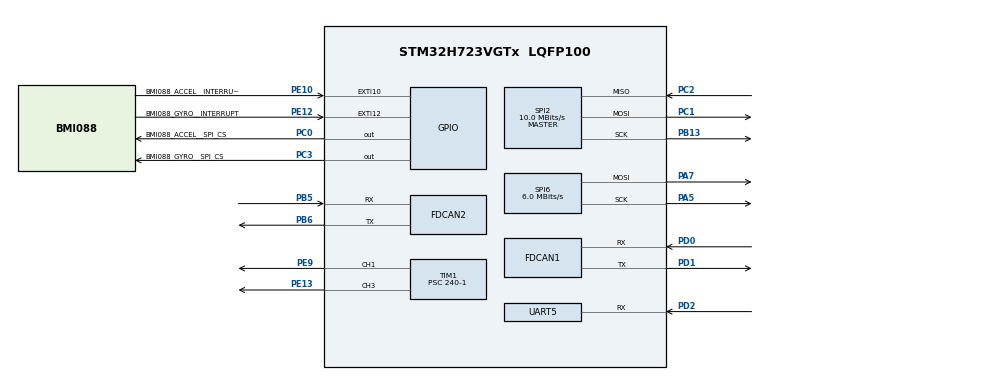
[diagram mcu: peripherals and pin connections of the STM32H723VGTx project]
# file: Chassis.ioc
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CORTEX_M7.CPU_DCache=Disabled
CORTEX_M7.CPU_ICache=Disabled
Dma.Request0=UART5_RX
Dma.UART5_RX.0.Direction=DMA_PERIPH_TO_MEMORY
Dma.UART5_RX.0.EventEnable=DISABLE
Dma.UART5_RX.0.FIFOMode=DMA_FIFOMODE_DISABLE
Dma.UART5_RX.0.Instance=DMA1_Stream1
Dma.UART5_RX.0.MemDataAlignment=DMA_MDATAALIGN_BYTE
Dma.UART5_RX.0.MemInc=DMA_MINC_ENABLE
Dma.UART5_RX.0.Mode=DMA_NORMAL
Dma.UART5_RX.0.PeriphDataAlignment=DMA_PDATAALIGN_BYTE
Dma.UART5_RX.0.PeriphInc=DMA_PINC_DISABLE
Dma.UART5_RX.0.Polarity=HAL_DMAMUX_REQ_GEN_RISING
Dma.UART5_RX.0.Priority=DMA_PRIORITY_VERY_HIGH
Dma.UART5_RX.0.RequestNumber=1
Dma.UART5_RX.0.SignalID=NONE
Dma.UART5_RX.0.SyncEnable=DISABLE
Dma.UART5_RX.0.SyncPolarity=HAL_DMAMUX_SYNC_NO_EVENT
Dma.UART5_RX.0.SyncRequestNumber=1
Dma.UART5_RX.0.SyncSignalID=NONE
FDCAN1.AutoRetransmission=ENABLE
FDCAN1.CalculateBaudRateNominal=1000000
FDCAN1.CalculateTimeBitNominal=1000
FDCAN1.CalculateTimeQuantumNominal=25.0
FDCAN1.DataPrescaler=3
FDCAN1.DataSyncJumpWidth=10
FDCAN1.DataTimeSeg1=29
FDCAN1.DataTimeSeg2=10
FDCAN1.ExtFiltersNbr=0
FDCAN1.FrameFormat=FDCAN_FRAME_CLASSIC
FDCAN1.Mode=FDCAN_MODE_NORMAL
FDCAN1.NominalPrescaler=3
FDCAN1.NominalSyncJumpWidth=10
FDCAN1.NominalTimeSeg1=29
FDCAN1.NominalTimeSeg2=10
FDCAN1.ProtocolException=DISABLE
FDCAN1.RxBuffersNbr=0
FDCAN1.RxFifo0ElmtsNbr=4
FDCAN1.RxFifo1ElmtsNbr=0
FDCAN1.StdFiltersNbr=1
FDCAN1.TransmitPause=ENABLE
FDCAN1.TxBuffersNbr=0
FDCAN1.TxEventsNbr=0
FDCAN1.TxFifoQueueElmtsNbr=4
FDCAN2.AutoRetransmission=ENABLE
FDCAN2.CalculateBaudRateNominal=1000000
FDCAN2.CalculateTimeBitNominal=1000
FDCAN2.CalculateTimeQuantumNominal=25.0
FDCAN2.DataPrescaler=3
FDCAN2.DataSyncJumpWidth=10
FDCAN2.DataTimeSeg1=29
FDCAN2.DataTimeSeg2=10
FDCAN2.ExtFiltersNbr=0
FDCAN2.FrameFormat=FDCAN_FRAME_CLASSIC
FDCAN2.MessageRAMOffset=0x406
FDCAN2.Mode=FDCAN_MODE_NORMAL
FDCAN2.NominalPrescaler=3
FDCAN2.NominalSyncJumpWidth=10
FDCAN2.NominalTimeSeg1=29
FDCAN2.NominalTimeSeg2=10
FDCAN2.ProtocolException=DISABLE
FDCAN2.RxBuffersNbr=0
FDCAN2.RxFifo0ElmtsNbr=4
FDCAN2.RxFifo1ElmtsNbr=0
FDCAN2.StdFiltersNbr=1
FDCAN2.TransmitPause=ENABLE
FDCAN2.TxBuffersNbr=0
FDCAN2.TxEventsNbr=0
FDCAN2.TxFifoQueueElmtsNbr=4
FREERTOS.Tasks01=defaultTask,24,128,StartDefaultTask,Default,NULL,Dynamic,NULL,NULL;ChassisTask,40,512,Chassis_Task,As external,NULL,Dynamic,NULL,NULL;CommunicateTask,24,512,Communicate_Task,As external,NULL,Dynamic,NULL,NULL;ShootTask,32,512,Shoot_Task,As external,NULL,Dynamic,NULL,NULL
Mcu.Family=STM32H7
Mcu.Name=STM32H723VGTx
Mcu.Package=LQFP100
NVIC.DMA1_Stream1_IRQn=true\:5\:0\:false\:false\:true\:false\:false\:true\:true
NVIC.EXTI15_10_IRQn=true\:5\:0\:false\:false\:true\:true\:true\:true\:true
NVIC.FDCAN1_IT0_IRQn=true\:5\:0\:true\:false\:true\:true\:true\:true\:true
NVIC.FDCAN1_IT1_IRQn=true\:5\:0\:true\:false\:true\:true\:true\:true\:true
NVIC.FDCAN2_IT0_IRQn=true\:5\:0\:false\:false\:true\:true\:true\:true\:true
NVIC.FDCAN2_IT1_IRQn=true\:5\:0\:false\:false\:true\:true\:true\:true\:true
NVIC.PriorityGroup=NVIC_PRIORITYGROUP_4
NVIC.TIM23_IRQn=true\:15\:0\:false\:false\:true\:false\:false\:true\:true
NVIC.TimeBase=TIM23_IRQn
NVIC.TimeBaseIP=TIM23
NVIC.UART5_IRQn=true\:5\:0\:false\:false\:true\:true\:true\:true\:true
PA13(JTMS/SWDIO).Mode=Serial_Wire
PA13(JTMS/SWDIO).Signal=DEBUG_JTMS-SWDIO
PA14(JTCK/SWCLK).Mode=Serial_Wire
PA14(JTCK/SWCLK).Signal=DEBUG_JTCK-SWCLK
PA5.Mode=TX_Only_Simplex_Unidirect_Master
PA5.Signal=SPI6_SCK
PA7.Mode=TX_Only_Simplex_Unidirect_Master
PA7.Signal=SPI6_MOSI
PB13.Mode=Full_Duplex_Master
PB13.Signal=SPI2_SCK
PB5.Mode=FDCAN_Activate
PB5.Signal=FDCAN2_RX
PB6.Mode=FDCAN_Activate
PB6.Signal=FDCAN2_TX
PD0.Mode=FDCAN_Activate
PD0.Signal=FDCAN1_RX
PD1.Mode=FDCAN_Activate
PD1.Signal=FDCAN1_TX
PD2.Mode=Asynchronous
PD2.Signal=UART5_RX
PC0.GPIO_Label=BMI088_ACCEL__SPI_CS
PC0.Signal=GPIO_Output
PC1.Mode=Full_Duplex_Master
PC1.Signal=SPI2_MOSI
PC2.Mode=Full_Duplex_Master
PC2.Signal=SPI2_MISO
PC3.GPIO_Label=BMI088_GYRO__SPI_CS
PC3.Signal=GPIO_Output
PE10.GPIO_Label=BMI088_ACCEL__INTERRUPT
PE10.GPIO_PuPd=GPIO_PULLDOWN
PE10.Signal=GPXTI10
PE12.GPIO_Label=BMI088_GYRO__INTERRUPT
PE12.GPIO_PuPd=GPIO_PULLDOWN
PE12.Signal=GPXTI12
PE13.GPIO_PuPd=GPIO_PULLDOWN
PE13.Signal=S_TIM1_CH3
PE9.GPIO_PuPd=GPIO_PULLDOWN
PE9.Signal=S_TIM1_CH1
PH0-OSC_IN.Mode=HSE-External-Oscillator
PH0-OSC_IN.Signal=RCC_OSC_IN
PH1-OSC_OUT.Mode=HSE-External-Oscillator
PH1-OSC_OUT.Signal=RCC_OSC_OUT
ProjectManager.HeapSize=0x200
ProjectManager.StackSize=0x800
ProjectManager.TargetToolchain=MDK-ARM V5.32
RCC.ADCFreq_Value=48375000
RCC.APB1Freq_Value=120000000
RCC.APB2Freq_Value=120000000
RCC.APB3Freq_Value=120000000
RCC.APB4Freq_Value=120000000
RCC.CortexFreq_Value=480000000
RCC.D1PPRE=RCC_APB3_DIV2
RCC.D2PPRE1=RCC_APB1_DIV2
RCC.D2PPRE2=RCC_APB2_DIV2
RCC.D3PPRE=RCC_APB4_DIV2
RCC.DIVM1=2
RCC.DIVN1=40
RCC.DIVP1=1
RCC.DIVQ1=4
RCC.HCLKFreq_Value=240000000
RCC.HPRE=RCC_HCLK_DIV2
RCC.HSE_VALUE=24000000
RCC.PLLFRACN=0
RCC.PLLSourceVirtual=RCC_PLLSOURCE_HSE
RCC.SPI6CLockSelection=RCC_SPI6CLKSOURCE_HSE
RCC.SYSCLKFreq_VALUE=480000000
RCC.SYSCLKSource=RCC_SYSCLKSOURCE_PLLCLK
RCC.USBFreq_Value=120000000
SH.S_TIM1_CH1.0=TIM1_CH1,PWM Generation1 CH1
SH.S_TIM1_CH3.0=TIM1_CH3,PWM Generation3 CH3
SPI2.BaudRatePrescaler=SPI_BAUDRATEPRESCALER_8
SPI2.CLKPhase=SPI_PHASE_2EDGE
SPI2.CLKPolarity=SPI_POLARITY_HIGH
SPI2.CalculateBaudRate=10.0 MBits/s
SPI2.DataSize=SPI_DATASIZE_8BIT
SPI2.Direction=SPI_DIRECTION_2LINES
SPI2.Mode=SPI_MODE_MASTER
SPI2.VirtualType=VM_MASTER
SPI6.BaudRatePrescaler=SPI_BAUDRATEPRESCALER_4
SPI6.CLKPhase=SPI_PHASE_2EDGE
SPI6.CalculateBaudRate=6.0 MBits/s
SPI6.DataSize=SPI_DATASIZE_8BIT
SPI6.Direction=SPI_DIRECTION_2LINES_TXONLY
SPI6.Mode=SPI_MODE_MASTER
SPI6.VirtualType=VM_MASTER
TIM1.AutoReloadPreload=TIM_AUTORELOAD_PRELOAD_ENABLE
TIM1.Channel-PWM\ Generation1\ CH1=TIM_CHANNEL_1
TIM1.Channel-PWM\ Generation3\ CH3=TIM_CHANNEL_3
TIM1.Period=2000-1
TIM1.Prescaler=240-1
UART5.BaudRate=100000
UART5.Mode=MODE_RX
UART5.Parity=PARITY_EVEN
UART5.StopBits=UART_STOPBITS_2
UART5.WordLength=WORDLENGTH_9B
VP_FREERTOS_VS_CMSIS_V2.Mode=CMSIS_V2
VP_MEMORYMAP_VS_MEMORYMAP.Mode=CurAppReg
VP_SYS_VS_tim23.Mode=TIM23
VP_TIM1_VS_ClockSourceINT.Mode=Internal
board=custom

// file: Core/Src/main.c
/* USER CODE BEGIN Header */
/**
  ******************************************************************************
  * @file           : main.c
  * @brief          : Main program body
  ******************************************************************************
  * @attention
  *
  * Copyright (c) 2026 STMicroelectronics.
  * All rights reserved.
  *
  * This software is licensed under terms that can be found in the LICENSE file
  * in the root directory of this software component.
  * If no LICENSE file comes with this software, it is provided AS-IS.
  *
  ******************************************************************************
  */
/* USER CODE END Header */
#include "main.h"
#include "FreeRTOS.h"
#include "cmsis_os2.h"
#include "dma.h"
#include "fdcan.h"
#include "spi.h"
#include "tim.h"
#include "usart.h"
#include "gpio.h"

/* USER CODE BEGIN Includes */
#include "bsp_fdcan.h"
#include "bsp_pwm.h"
extern void i6x_remote_init(void);
/* USER CODE END Includes */

void SystemClock_Config(void);
void MX_FREERTOS_Init(void);

int main(void)
{

  /* MCU Configuration--------------------------------------------------------*/

  /* Reset of all peripherals, Initializes the Flash interface and the Systick. */
  HAL_Init();

  /* Configure the system clock */
  SystemClock_Config();

  /* Initialize all configured peripherals */
  MX_GPIO_Init();
  MX_DMA_Init();
  MX_FDCAN1_Init();
  MX_FDCAN2_Init();
  MX_SPI2_Init();
  MX_SPI6_Init();
  MX_UART5_Init();
  MX_TIM1_Init();
  /* USER CODE BEGIN 2 */
  can_bsp_init();
  i6x_remote_init();
  pwm_init();
  /* USER CODE END 2 */

  /* Init scheduler */
  osKernelInitialize();  /* Call init function for freertos objects (in cmsis_os2.c) */
  MX_FREERTOS_Init();

  /* Start scheduler */
  osKernelStart();

  /* We should never get here as control is now taken by the scheduler */

  /* Infinite loop */
  while (1)
  {

  }
}

void SystemClock_Config(void)
{
  RCC_OscInitTypeDef RCC_OscInitStruct = {0};
  RCC_ClkInitTypeDef RCC_ClkInitStruct = {0};

  /** Supply configuration update enable
  */
  HAL_PWREx_ConfigSupply(PWR_LDO_SUPPLY);

  /** Configure the main internal regulator output voltage
  */
  __HAL_PWR_VOLTAGESCALING_CONFIG(PWR_REGULATOR_VOLTAGE_SCALE0);

  while(!__HAL_PWR_GET_FLAG(PWR_FLAG_VOSRDY)) {}

  /** Initializes the RCC Oscillators according to the specified parameters
  * in the RCC_OscInitTypeDef structure.
  */
  RCC_OscInitStruct.OscillatorType = RCC_OSCILLATORTYPE_HSE;
  RCC_OscInitStruct.HSEState = RCC_HSE_ON;
  RCC_OscInitStruct.PLL.PLLState = RCC_PLL_ON;
  RCC_OscInitStruct.PLL.PLLSource = RCC_PLLSOURCE_HSE;
  RCC_OscInitStruct.PLL.PLLM = 2;
  RCC_OscInitStruct.PLL.PLLN = 40;
  RCC_OscInitStruct.PLL.PLLP = 1;
  RCC_OscInitStruct.PLL.PLLQ = 4;
  RCC_OscInitStruct.PLL.PLLR = 2;
  RCC_OscInitStruct.PLL.PLLRGE = RCC_PLL1VCIRANGE_3;
  RCC_OscInitStruct.PLL.PLLVCOSEL = RCC_PLL1VCOWIDE;
  RCC_OscInitStruct.PLL.PLLFRACN = 0;
  if (HAL_RCC_OscConfig(&RCC_OscInitStruct) != HAL_OK)
  {
    Error_Handler();
  }

  /** Initializes the CPU, AHB and APB buses clocks
  */
  RCC_ClkInitStruct.ClockType = RCC_CLOCKTYPE_HCLK|RCC_CLOCKTYPE_SYSCLK
                              |RCC_CLOCKTYPE_PCLK1|RCC_CLOCKTYPE_PCLK2
                              |RCC_CLOCKTYPE_D3PCLK1|RCC_CLOCKTYPE_D1PCLK1;
  RCC_ClkInitStruct.SYSCLKSource = RCC_SYSCLKSOURCE_PLLCLK;
  RCC_ClkInitStruct.SYSCLKDivider = RCC_SYSCLK_DIV1;
  RCC_ClkInitStruct.AHBCLKDivider = RCC_HCLK_DIV2;
  RCC_ClkInitStruct.APB3CLKDivider = RCC_APB3_DIV2;
  RCC_ClkInitStruct.APB1CLKDivider = RCC_APB1_DIV2;
  RCC_ClkInitStruct.APB2CLKDivider = RCC_APB2_DIV2;
  RCC_ClkInitStruct.APB4CLKDivider = RCC_APB4_DIV2;

  if (HAL_RCC_ClockConfig(&RCC_ClkInitStruct, FLASH_LATENCY_3) != HAL_OK)
  {
    Error_Handler();
  }
}

void HAL_TIM_PeriodElapsedCallback(TIM_HandleTypeDef *htim)
{
  if (htim->Instance == TIM23)
  {
    HAL_IncTick();
  }
}

void Error_Handler(void)
{
  __disable_irq();
  while (1)
  {
  }
}

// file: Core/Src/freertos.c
/* USER CODE BEGIN Header */
/**
  ******************************************************************************
  * File Name          : freertos.c
  * Description        : Code for freertos applications
  ******************************************************************************
  * @attention
  *
  * Copyright (c) 2026 STMicroelectronics.
  * All rights reserved.
  *
  * This software is licensed under terms that can be found in the LICENSE file
  * in the root directory of this software component.
  * If no LICENSE file comes with this software, it is provided AS-IS.
  *
  ******************************************************************************
  */
/* USER CODE END Header */

#include "FreeRTOS.h"
#include "task.h"
#include "main.h"
#include "FreeRTOS.h"
#include "cmsis_os2.h"

/* USER CODE BEGIN Includes */
#include "chassis_task.h"
#include "communicate_task.h"
#include "gimbal_task.h"
/* USER CODE END Includes */

/* Definitions for defaultTask */
osThreadId_t defaultTaskHandle;
const osThreadAttr_t defaultTask_attributes = {
  .name = "defaultTask",
  .stack_size = 128 * 4,
  .priority = (osPriority_t) osPriorityNormal,
};
/* Definitions for ChassisTask */
osThreadId_t ChassisTaskHandle;
const osThreadAttr_t ChassisTask_attributes = {
  .name = "ChassisTask",
  .stack_size = 512 * 4,
  .priority = (osPriority_t) osPriorityHigh,
};
/* Definitions for CommunicateTask */
osThreadId_t CommunicateTaskHandle;
const osThreadAttr_t CommunicateTask_attributes = {
  .name = "CommunicateTask",
  .stack_size = 512 * 4,
  .priority = (osPriority_t) osPriorityNormal,
};
/* Definitions for GimbalTask */
osThreadId_t GimbalTaskHandle;
const osThreadAttr_t GimbalTask_attributes = {
  .name = "GimbalTask",
  .stack_size = 512 * 4,
  .priority = (osPriority_t) osPriorityHigh,
};
/* Definitions for ShootTask */
osThreadId_t ShootTaskHandle;
const osThreadAttr_t ShootTask_attributes = {
  .name = "ShootTask",
  .stack_size = 512 * 4,
  .priority = (osPriority_t) osPriorityAboveNormal,
};

void StartDefaultTask(void *argument);
extern void Chassis_Task(void *argument);
extern void Communicate_Task(void *argument);
extern void Gimbal_Task(void *argument);
extern void Shoot_Task(void *argument);

void MX_FREERTOS_Init(void); /* (MISRA C 2004 rule 8.1) */

void MX_FREERTOS_Init(void) {

  /* Create the thread(s) */
  /* creation of defaultTask */
  defaultTaskHandle = osThreadNew(StartDefaultTask, NULL, &defaultTask_attributes);

  /* creation of ChassisTask */
  ChassisTaskHandle = osThreadNew(Chassis_Task, NULL, &ChassisTask_attributes);

  /* creation of CommunicateTask */
  CommunicateTaskHandle = osThreadNew(Communicate_Task, NULL, &CommunicateTask_attributes);

  /* creation of GimbalTask */
  GimbalTaskHandle = osThreadNew(Gimbal_Task, NULL, &GimbalTask_attributes);
  /* creation of ShootTask */
  ShootTaskHandle = osThreadNew(Shoot_Task, NULL, &ShootTask_attributes);

}

void StartDefaultTask(void *argument)
{
  for(;;)
  {
    osDelay(1);
  }
}
